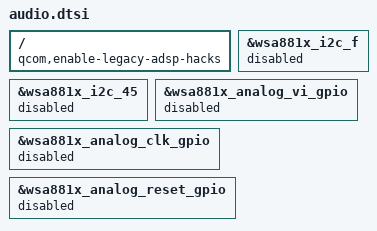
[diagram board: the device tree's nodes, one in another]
/ {
	qcom,enable-legacy-adsp-hacks;
};

&wsa881x_i2c_f {
        status = "disabled";
};

&wsa881x_i2c_45 {
        status = "disabled";
};

&wsa881x_analog_vi_gpio {
        status = "disabled";
};

&wsa881x_analog_clk_gpio {
        status = "disabled";
};

&wsa881x_analog_reset_gpio {
        status = "disabled";
};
